# S6E1B8xE register map
Vendor: Cypress; File version: 2.1
CPU: CM0PLUS r0p1, little endian, no MPU, no FPU, 2 interrupt priority bits
Registers are 8-bit, read-write, reset 0x0 unless marked. A register's access mark holds for its fields unless they carry their own. Offsets are from the block's base; [hi:lo] are bit positions.

## CRG — Clock Unit Registers
Base 0x40010000
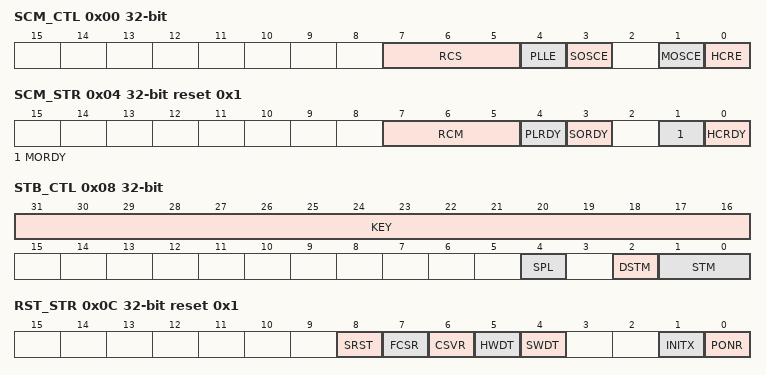
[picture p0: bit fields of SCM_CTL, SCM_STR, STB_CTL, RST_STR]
0x00 SCM_CTL 32-bit — System Clock Mode Control Register [W]
  [7:5] RCS — Master clock switch control bits
  [4] PLLE — PLL oscillation enable bit
  [3] SOSCE — Sub clock oscillation enable bit
  [1] MOSCE — Main clock oscillation enable bit
  [0] HCRE — High-speed CR clock oscillation enable bit
0x04 SCM_STR 32-bit ro reset 0x1 — System Clock Mode Status Register [W]
  [7:5] RCM — Master clock selection bits
  [4] PLRDY — PLL oscillation stable bit
  [3] SORDY — Sub clock oscillation stable bit
  [1] MORDY — Main clock oscillation stable bit
  [0] HCRDY — High-speed CR clock oscillation stable bit
0x08 STB_CTL 32-bit — Standby Mode Control Register [W]
  [31:16] KEY — Standby mode control write control bits
  [4] SPL — Standby pin level setting bit
  [2] DSTM — Deep standby mode select bit
  [1:0] STM — Standby mode selection bits
0x0C RST_STR 32-bit ro reset 0x1 — Reset Cause Register [W]
  [8] SRST — Software reset flag
  [7] FCSR — Flag for anomalous frequency detection reset
  [6] CSVR — Clock failure detection reset flag
  [5] HWDT — Hardware watchdog reset flag
  [4] SWDT — Software watchdog reset flag
  [1] INITX — INITX pin input reset flag
  [0] PONR — Power-on reset/low-voltage detection reset flag
0x10 BSC_PSR 32-bit — Base Clock Prescaler Register [W]
  [2:0] BSR — Base clock frequency division ratio setting bits
0x14 APBC0_PSR 32-bit — APB0 Prescaler Register [W]
  [1:0] APBC0 — APB0 bus clock frequency division ratio setting bits
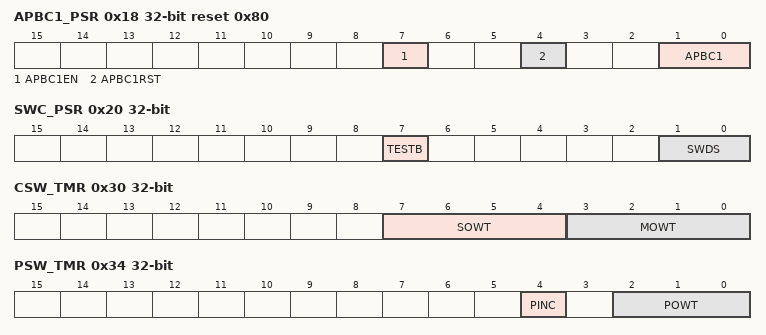
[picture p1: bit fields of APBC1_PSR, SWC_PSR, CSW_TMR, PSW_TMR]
0x18 APBC1_PSR 32-bit reset 0x80 — APB1 Prescaler Register [W]
  [7] APBC1EN — APB1 clock enable bit
  [4] APBC1RST — APB1 bus reset control bit [W]
  [1:0] APBC1 — APB1 bus clock frequency division ratio setting bits
0x20 SWC_PSR 32-bit — Software Watchdog Clock Prescaler Register [W]
  [7] TESTB — TEST bit
  [1:0] SWDS — Software watchdog clock frequency division ratio setting bits
0x30 CSW_TMR 32-bit — Clock Stabilization Wait Time Register [W]
  [7:4] SOWT — Sub clock stabilization wait time setup bits
  [3:0] MOWT — Main clock stabilization wait time setup bits
0x34 PSW_TMR 32-bit — PLL Clock Stabilization Wait Time Setup Register [W]
  [4] PINC — PLL input clock select bit
  [2:0] POWT — Main PLL clock stabilization wait time setup bits
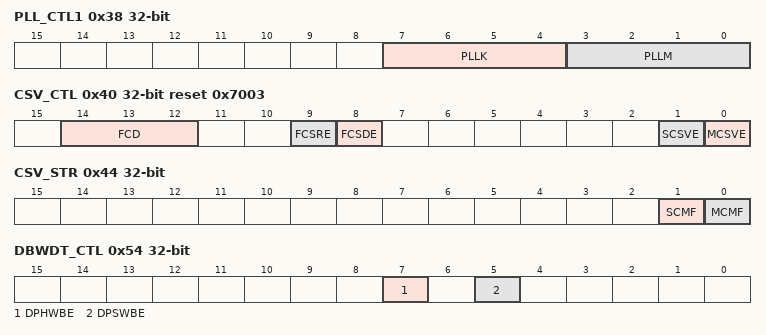
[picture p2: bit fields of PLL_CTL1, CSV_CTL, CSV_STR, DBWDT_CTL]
0x38 PLL_CTL1 32-bit — PLL Control Register 1 [W]
  [7:4] PLLK — PLL input clock frequency division ratio setting bits
  [3:0] PLLM — PLL VCO clock frequency division ratio setting bits
0x3C PLL_CTL2 32-bit — PLL Control Register 2 [W]
  [5:0] PLLN — PLL feedback frequency division ratio setting bits
0x40 CSV_CTL 32-bit reset 0x7003 — CSV control register [W]
  [14:12] FCD — FCS count cycle setting bits
  [9] FCSRE — FCS reset output enable bit
  [8] FCSDE — FCS function enable bit
  [1] SCSVE — Sub CSV function enable bit
  [0] MCSVE — Main CSV function enable bit
0x44 CSV_STR 32-bit ro — CSV status register [W]
  [1] SCMF — Sub clock failure detection flag
  [0] MCMF — Main clock failure detection flag
0x48 FCSWH_CTL 32-bit reset 0xFFFF — Frequency detection window setting register [W]
  [15:0] FWH — Frequency detection window setting bits (Upper)
0x4C FCSWL_CTL 32-bit — Frequency detection window setting register [W]
  [15:0] FWL — Frequency detection window setting bits (Lower)
0x50 FCSWD_CTL 32-bit ro — Frequency detection counter register [W]
  [15:0] FWD — Frequency detection count data
0x54 DBWDT_CTL 32-bit — Debug Break Watchdog Timer Control Register [W]
  [7] DPHWBE — HW-WDG debug mode break bit
  [5] DPSWBE — SW-WDG debug mode break bit
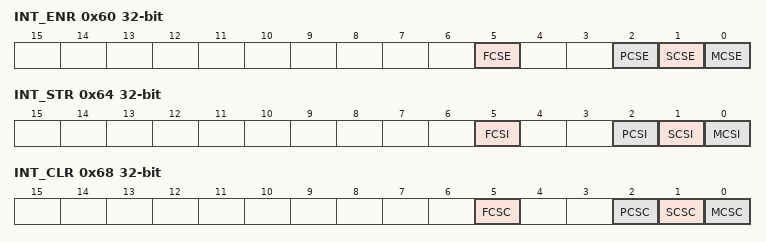
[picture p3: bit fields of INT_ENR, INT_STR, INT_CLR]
0x60 INT_ENR 32-bit — Interrupt Enable Register [W]
  [5] FCSE — Anomalous frequency detection interrupt enable bit
  [2] PCSE — PLL oscillation stabilization wait completion interrupt enable bit
  [1] SCSE — Sub clock oscillation stabilization wait completion interrupt enable bit
  [0] MCSE — Main clock oscillation stabilization wait completion interrupt enable bit
0x64 INT_STR 32-bit ro — Interrupt Status Register [W]
  [5] FCSI — Anomalous frequency detection interrupt status bit
  [2] PCSI — PLL oscillation stabilization wait completion interrupt status bit
  [1] SCSI — Sub clock oscillation stabilization wait completion interrupt status bit
  [0] MCSI — Main clock oscillation stabilization wait completion interrupt status bit
0x68 INT_CLR 32-bit wo — Interrupt Clear Register [W]
  [5] FCSC — Anomalous frequency detection interrupt factor clear bit
  [2] PCSC — PLL oscillation stabilization wait completion interrupt factor clear bit
  [1] SCSC — Sub clock oscillation stabilization wait completion interrupt factor clear bit
  [0] MCSC — Main clock oscillation stabilization wait completion interrupt factor clear bit

## Notices in the file
Copyright (C) 2013-2016, Cypress Semiconductor Corporation or a
subsidiary of Cypress Semiconductor Corporation.  All rights reserved.
This software, including source code, documentation and related
materials ("Software"), is owned by Cypress Semiconductor Corporation or
one of its subsidiaries ("Cypress") and is protected by and subject to
worldwide patent protection (United States and foreign), United States
copyright laws and international treaty provisions. Therefore, you may use
this Software only as provided in the license agreement accompanying the
software package from which you obtained this Software ("EULA").
If no EULA applies, Cypress hereby grants you a personal, non-exclusive,
non-transferable license to copy, modify, and compile the
Software source code solely for use in connection with Cypress's
integrated circuit products.  Any reproduction, modification, translation,
compilation, or representation of this Software except as specified
above is prohibited without the express written permission of Cypress.
Disclaimer: THIS SOFTWARE IS PROVIDED AS-IS, WITH NO
WARRANTY OF ANY KIND, EXPRESS OR IMPLIED, INCLUDING,
BUT NOT LIMITED TO, NONINFRINGEMENT, IMPLIED
WARRANTIES OF MERCHANTABILITY AND FITNESS FOR A
PARTICULAR PURPOSE. Cypress reserves the right to make
changes to the Software without notice. Cypress does not assume any
liability arising out of the application or use of the Software or any
product or circuit described in the Software. Cypress does not
authorize its products for use in any products where a malfunction or
failure of the Cypress product may reasonably be expected to result in
significant property damage, injury or death ("High Risk Product"). By
including Cypress's product in a High Risk Product, the manufacturer
of such system or application assumes all risk of such use and in doing
so agrees to indemnify Cypress against all liability.
